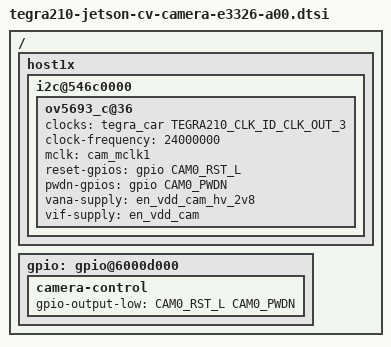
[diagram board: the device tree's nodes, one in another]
/*
 * Copyright (c) 2015, NVIDIA CORPORATION.  All rights reserved.
 *
 * This program is free software; you can redistribute it and/or modify
 * it under the terms of the GNU General Public License as published by
 * the Free Software Foundation; either version 2 of the License, or
 * (at your option) any later version.
 *
 * This program is distributed in the hope that it will be useful, but WITHOUT
 * ANY WARRANTY; without even the implied warranty of MERCHANTABILITY or
 * FITNESS FOR A PARTICULAR PURPOSE.  See the GNU General Public License for
 * more details.
 *
 * You should have received a copy of the GNU General Public License
 * along with this program.  If not, see <http://www.gnu.org/licenses/>.
 */

#include <tegra210-platforms/tegra210-camera-e3326-a00.dtsi>

#define CAM0_RST_L	TEGRA_GPIO(S, 4)
#define CAM0_PWDN	TEGRA_GPIO(S, 7)

/* camera control gpio definitions */

/ {
	host1x {
		i2c@546c0000 {
			ov5693_c@36 {
				/* Define any required hw resources needed by driver */
				/* ie. clocks, io pins, power sources */
				/* mclk-index indicates the index of the */
				/* mclk-name with in the clock-names array */

				clocks = <&tegra_car TEGRA210_CLK_ID_CLK_OUT_3>;
				clock-names = "mclk";
				clock-frequency = <24000000>;

				mclk = "cam_mclk1";
				reset-gpios = <&gpio CAM0_RST_L GPIO_ACTIVE_HIGH>;
				pwdn-gpios = <&gpio CAM0_PWDN GPIO_ACTIVE_HIGH>;
				vana-supply = <&en_vdd_cam_hv_2v8>;
				vif-supply = <&en_vdd_cam>;
			};
		};
	};

	gpio: gpio@6000d000 {
		camera-control {
			gpio-output-low = <
				CAM0_RST_L
				CAM0_PWDN
				>;
		};
	};
};
